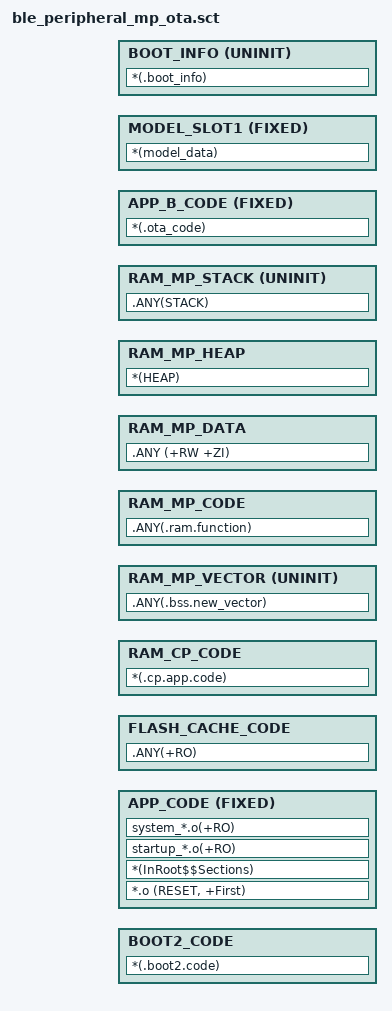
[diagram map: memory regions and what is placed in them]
#! armclang --target=arm-arm-none-eabi -mcpu=cortex-m33 -E -x c

#include "..\..\config\app_cfg_ota.h"


LOAD_BOOT2 FLASH_BASE_ADDR FLASH_2ND_BOOT_SIZE_MAX
{
    BOOT2_CODE +0
    {
        *(.boot2.code)
    }
}

LOAD_APP FLASH_APP_A_ADDR FLASH_APP_A_SIZE
{
    APP_CODE +0 FIXED
    {
        *.o (RESET, +First)
        *(InRoot$$Sections)
        startup_*.o(+RO)
        system_*.o(+RO)
    }

    FLASH_CACHE_CODE +0
    {
        .ANY(+RO)
    }

    RAM_CP_CODE RAM_CP_ADDR RAM_CP_SIZE_MAX
    {
        *(.cp.app.code)
    }

    RAM_MP_VECTOR RAM_MP_VECTOR_ADDR UNINIT RAM_MP_VECTOR_SIZE_MAX
    {
        .ANY(.bss.new_vector)
    }

    RAM_MP_CODE RAM_MP_CODE_ADDR RAM_MP_CODE_SIZE_MAX
    {
        .ANY(.ram.function)
    }

    RAM_MP_DATA RAM_MP_DATA_ADDR RAM_MP_DATA_SIZE_MAX
    {
        .ANY (+RW +ZI)
    }

    RAM_MP_HEAP RAM_MP_HEAP_ADDR RAM_MP_HEAP_SIZE_MAX
    {
        *(HEAP)
    }

    RAM_MP_STACK RAM_MP_STACK_ADDR UNINIT RAM_MP_STACK_SIZE_MAX
    {
        .ANY(STACK)
    }
}

// OTA 目标区 (Bank B)
LOAD_OTA APP_B_CODE FLASH_APP_B_ADDR
{
    APP_B_CODE +0 FIXED
    {
        *(.ota_code)
    }
}

// 模型数据存储区
LOAD_MODEL MODEL_SLOT1 FLASH_MODEL_SLOT1_ADDR
{
    MODEL_SLOT1 +0 FIXED
    {
        *(model_data)
    }
}

// Bootloader 信息区
LOAD_BOOT_INFO BOOT_INFO FLASH_BOOT_INFO_ADDR
{
    BOOT_INFO +0 UNINIT
    {
        *(.boot_info)
    }
}
